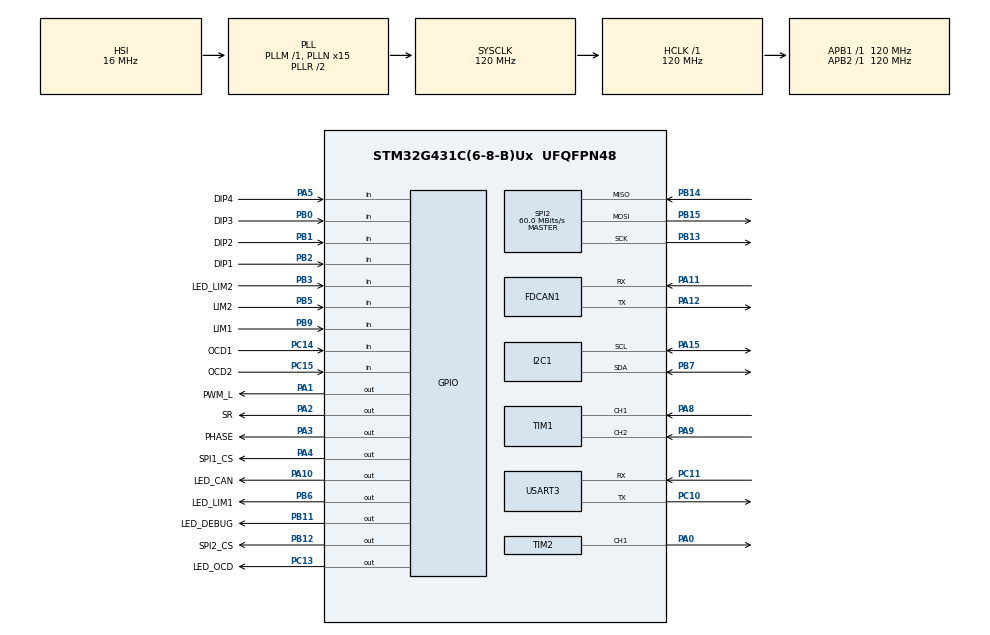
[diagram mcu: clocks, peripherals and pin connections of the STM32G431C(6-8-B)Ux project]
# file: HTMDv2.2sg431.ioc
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Dma.Request0=USART3_RX
Dma.Request1=USART3_TX
Dma.Request2=SPI2_RX
Dma.Request3=SPI2_TX
Dma.SPI2_RX.2.Direction=DMA_PERIPH_TO_MEMORY
Dma.SPI2_RX.2.EventEnable=DISABLE
Dma.SPI2_RX.2.Instance=DMA1_Channel5
Dma.SPI2_RX.2.MemDataAlignment=DMA_MDATAALIGN_BYTE
Dma.SPI2_RX.2.MemInc=DMA_MINC_ENABLE
Dma.SPI2_RX.2.Mode=DMA_NORMAL
Dma.SPI2_RX.2.PeriphDataAlignment=DMA_PDATAALIGN_BYTE
Dma.SPI2_RX.2.PeriphInc=DMA_PINC_DISABLE
Dma.SPI2_RX.2.Polarity=HAL_DMAMUX_REQ_GEN_RISING
Dma.SPI2_RX.2.Priority=DMA_PRIORITY_LOW
Dma.SPI2_RX.2.RequestNumber=1
Dma.SPI2_RX.2.SignalID=NONE
Dma.SPI2_RX.2.SyncEnable=DISABLE
Dma.SPI2_RX.2.SyncPolarity=HAL_DMAMUX_SYNC_NO_EVENT
Dma.SPI2_RX.2.SyncRequestNumber=1
Dma.SPI2_RX.2.SyncSignalID=NONE
Dma.SPI2_TX.3.Direction=DMA_MEMORY_TO_PERIPH
Dma.SPI2_TX.3.EventEnable=DISABLE
Dma.SPI2_TX.3.Instance=DMA1_Channel6
Dma.SPI2_TX.3.MemDataAlignment=DMA_MDATAALIGN_BYTE
Dma.SPI2_TX.3.MemInc=DMA_MINC_ENABLE
Dma.SPI2_TX.3.Mode=DMA_NORMAL
Dma.SPI2_TX.3.PeriphDataAlignment=DMA_PDATAALIGN_BYTE
Dma.SPI2_TX.3.PeriphInc=DMA_PINC_DISABLE
Dma.SPI2_TX.3.Polarity=HAL_DMAMUX_REQ_GEN_RISING
Dma.SPI2_TX.3.Priority=DMA_PRIORITY_LOW
Dma.SPI2_TX.3.RequestNumber=1
Dma.SPI2_TX.3.SignalID=NONE
Dma.SPI2_TX.3.SyncEnable=DISABLE
Dma.SPI2_TX.3.SyncPolarity=HAL_DMAMUX_SYNC_NO_EVENT
Dma.SPI2_TX.3.SyncRequestNumber=1
Dma.SPI2_TX.3.SyncSignalID=NONE
Dma.USART3_RX.0.Direction=DMA_PERIPH_TO_MEMORY
Dma.USART3_RX.0.EventEnable=DISABLE
Dma.USART3_RX.0.Instance=DMA1_Channel3
Dma.USART3_RX.0.MemDataAlignment=DMA_MDATAALIGN_BYTE
Dma.USART3_RX.0.MemInc=DMA_MINC_ENABLE
Dma.USART3_RX.0.Mode=DMA_NORMAL
Dma.USART3_RX.0.PeriphDataAlignment=DMA_PDATAALIGN_BYTE
Dma.USART3_RX.0.PeriphInc=DMA_PINC_DISABLE
Dma.USART3_RX.0.Polarity=HAL_DMAMUX_REQ_GEN_RISING
Dma.USART3_RX.0.Priority=DMA_PRIORITY_LOW
Dma.USART3_RX.0.RequestNumber=1
Dma.USART3_RX.0.SignalID=NONE
Dma.USART3_RX.0.SyncEnable=DISABLE
Dma.USART3_RX.0.SyncPolarity=HAL_DMAMUX_SYNC_NO_EVENT
Dma.USART3_RX.0.SyncRequestNumber=1
Dma.USART3_RX.0.SyncSignalID=NONE
Dma.USART3_TX.1.Direction=DMA_MEMORY_TO_PERIPH
Dma.USART3_TX.1.EventEnable=DISABLE
Dma.USART3_TX.1.Instance=DMA1_Channel4
Dma.USART3_TX.1.MemDataAlignment=DMA_MDATAALIGN_BYTE
Dma.USART3_TX.1.MemInc=DMA_MINC_ENABLE
Dma.USART3_TX.1.Mode=DMA_NORMAL
Dma.USART3_TX.1.PeriphDataAlignment=DMA_PDATAALIGN_BYTE
Dma.USART3_TX.1.PeriphInc=DMA_PINC_DISABLE
Dma.USART3_TX.1.Polarity=HAL_DMAMUX_REQ_GEN_RISING
Dma.USART3_TX.1.Priority=DMA_PRIORITY_LOW
Dma.USART3_TX.1.RequestNumber=1
Dma.USART3_TX.1.SignalID=NONE
Dma.USART3_TX.1.SyncEnable=DISABLE
Dma.USART3_TX.1.SyncPolarity=HAL_DMAMUX_SYNC_NO_EVENT
Dma.USART3_TX.1.SyncRequestNumber=1
Dma.USART3_TX.1.SyncSignalID=NONE
FDCAN1.CalculateBaudRateNominal=1000000
FDCAN1.CalculateTimeBitNominal=1000
FDCAN1.CalculateTimeQuantumNominal=100.0
FDCAN1.NominalPrescaler=3
FDCAN1.NominalTimeSeg1=7
FDCAN1.NominalTimeSeg2=2
I2C1.Timing=0x307075B1
Mcu.Family=STM32G4
Mcu.Name=STM32G431C(6-8-B)Ux
Mcu.Package=UFQFPN48
NVIC.DMA1_Channel3_IRQn=true\:0\:0\:false\:false\:true\:false\:true\:true
NVIC.DMA1_Channel4_IRQn=true\:0\:0\:false\:false\:true\:false\:true\:true
NVIC.DMA1_Channel5_IRQn=true\:0\:0\:false\:false\:true\:false\:true\:true
NVIC.DMA1_Channel6_IRQn=true\:0\:0\:false\:false\:true\:false\:true\:true
NVIC.FDCAN1_IT0_IRQn=true\:0\:0\:false\:false\:true\:true\:true\:true
NVIC.I2C1_ER_IRQn=true\:0\:0\:false\:false\:true\:true\:true\:true
NVIC.I2C1_EV_IRQn=true\:0\:0\:false\:false\:true\:true\:true\:true
NVIC.PriorityGroup=NVIC_PRIORITYGROUP_4
NVIC.TIM3_IRQn=true\:0\:0\:false\:false\:true\:true\:true\:true
NVIC.TIM4_IRQn=true\:0\:0\:false\:false\:true\:true\:true\:true
PA0.Signal=S_TIM2_CH1
PA1.GPIO_Label=PWM_L
PA1.Signal=GPIO_Output
PA10.GPIO_Label=LED_CAN
PA10.Signal=GPIO_Output
PA11.Mode=FDCAN_Activate
PA11.Signal=FDCAN1_RX
PA12.Mode=FDCAN_Activate
PA12.Signal=FDCAN1_TX
PA13.Mode=Serial_Wire
PA13.Signal=SYS_JTMS-SWDIO
PA14.Mode=Serial_Wire
PA14.Signal=SYS_JTCK-SWCLK
PA15.GPIO_Pu=GPIO_NOPULL
PA15.GPIO_Speed=GPIO_SPEED_FREQ_VERY_HIGH
PA15.Mode=I2C
PA15.Signal=I2C1_SCL
PA2.GPIO_Label=SR
PA2.Signal=GPIO_Output
PA3.GPIO_Label=PHASE
PA3.Signal=GPIO_Output
PA4.GPIO_Label=SPI1_CS
PA4.Signal=GPIO_Output
PA5.GPIO_Label=DIP4
PA5.GPIO_PuPd=GPIO_PULLDOWN
PA5.Signal=GPIO_Input
PA8.Signal=S_TIM1_CH1
PA9.Signal=S_TIM1_CH2
PB0.GPIO_Label=DIP3
PB0.GPIO_PuPd=GPIO_PULLDOWN
PB0.Signal=GPIO_Input
PB1.GPIO_Label=DIP2
PB1.GPIO_PuPd=GPIO_PULLDOWN
PB1.Signal=GPIO_Input
PB11.GPIO_Label=LED_DEBUG
PB11.Signal=GPIO_Output
PB12.GPIO_Label=SPI2_CS
PB12.Signal=GPIO_Output
PB13.Mode=Full_Duplex_Master
PB13.Signal=SPI2_SCK
PB14.Mode=Full_Duplex_Master
PB14.Signal=SPI2_MISO
PB15.Mode=Full_Duplex_Master
PB15.Signal=SPI2_MOSI
PB2.GPIO_Label=DIP1
PB2.GPIO_PuPd=GPIO_PULLDOWN
PB2.Signal=GPIO_Input
PB3.GPIO_Label=LED_LIM2
PB3.Signal=GPIO_Input
PB5.GPIO_Label=LIM2
PB5.GPIO_PuPd=GPIO_NOPULL
PB5.Signal=GPIO_Input
PB6.GPIO_Label=LED_LIM1
PB6.Signal=GPIO_Output
PB7.GPIO_Pu=GPIO_NOPULL
PB7.GPIO_Speed=GPIO_SPEED_FREQ_VERY_HIGH
PB7.Mode=I2C
PB7.Signal=I2C1_SDA
PB9.GPIO_Label=LIM1
PB9.Signal=GPIO_Input
PC10.Mode=Asynchronous
PC10.Signal=USART3_TX
PC11.Mode=Asynchronous
PC11.Signal=USART3_RX
PC13.GPIO_Label=LED_OCD
PC13.Signal=GPIO_Output
PC14-OSC32_IN.GPIO_Label=OCD1
PC14-OSC32_IN.Signal=GPIO_Input
PC15-OSC32_OUT.GPIO_Label=OCD2
PC15-OSC32_OUT.Signal=GPIO_Input
ProjectManager.HeapSize=0x200
ProjectManager.StackSize=0x400
ProjectManager.TargetToolchain=Makefile
RCC.ADC12Freq_Value=120000000
RCC.AHBFreq_Value=120000000
RCC.APB1Freq_Value=120000000
RCC.APB1TimFreq_Value=120000000
RCC.APB2Freq_Value=120000000
RCC.APB2TimFreq_Value=120000000
RCC.CortexFreq_Value=120000000
RCC.EXTERNAL_CLOCK_VALUE=12288000
RCC.FDCANCLockSelection=RCC_FDCANCLKSOURCE_PLL
RCC.HCLKFreq_Value=120000000
RCC.HSE_VALUE=8000000
RCC.HSI48_VALUE=48000000
RCC.HSI_VALUE=16000000
RCC.LSE_VALUE=32768
RCC.PLLN=15
RCC.PLLQ=RCC_PLLQ_DIV8
RCC.SYSCLKFreq_VALUE=120000000
RCC.SYSCLKSource=RCC_SYSCLKSOURCE_PLLCLK
RCC.USBFreq_Value=30000000
RCC.VCOOutputFreq_Value=240000000
SH.S_TIM1_CH1.0=TIM1_CH1,Encoder_Interface
SH.S_TIM1_CH2.0=TIM1_CH2,Encoder_Interface
SH.S_TIM2_CH1.0=TIM2_CH1,PWM Generation1 CH1
SPI2.CalculateBaudRate=60.0 MBits/s
SPI2.Direction=SPI_DIRECTION_2LINES
SPI2.Mode=SPI_MODE_MASTER
SPI2.VirtualType=VM_MASTER
TIM1.EncoderMode=TIM_ENCODERMODE_TI12
TIM2.Channel-PWM\ Generation1\ CH1=TIM_CHANNEL_1
TIM2.PeriodNoDither=5999
TIM2.Prescaler=0
TIM3.PeriodNoDither=999
TIM3.Prescaler=120
TIM4.PeriodNoDither=9999
TIM4.Prescaler=120
USART3.VirtualMode-Asynchronous=VM_ASYNC
VP_SYS_VS_DBSignals.Mode=DisableDeadBatterySignals
VP_TIM2_VS_ClockSourceINT.Mode=Internal
VP_TIM3_VS_ClockSourceINT.Mode=Internal
VP_TIM4_VS_ClockSourceINT.Mode=Internal
board=custom

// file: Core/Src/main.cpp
/* USER CODE BEGIN Header */
/**
 ******************************************************************************
 * @file           : main.c
 * @brief          : Main program body
 ******************************************************************************
 * @attention
 *
 * Copyright (c) 2024 STMicroelectronics.
 * All rights reserved.
 *
 * This software is licensed under terms that can be found in the LICENSE file
 * in the root directory of this software component.
 * If no LICENSE file comes with this software, it is provided AS-IS.
 *
 ******************************************************************************
 */
/* USER CODE END Header */
#include "main.h"
#include "dma.h"
#include "fdcan.h"
#include "i2c.h"
#include "spi.h"
#include "tim.h"
#include "usart.h"
#include "gpio.h"

/* USER CODE BEGIN Includes */
#include "app.hpp"

/* USER CODE END Includes */

void SystemClock_Config(void);

/* USER CODE BEGIN 0 */
App app;

/* USER CODE END 0 */

int main(void)
{

  /* MCU Configuration--------------------------------------------------------*/

  /* Reset of all peripherals, Initializes the Flash interface and the Systick. */
  HAL_Init();

  /* Configure the system clock */
  SystemClock_Config();

  /* Initialize all configured peripherals */
  MX_GPIO_Init();
  MX_DMA_Init();
  MX_FDCAN1_Init();
  MX_I2C1_Init();
  MX_TIM1_Init();
  MX_TIM2_Init();
  MX_USART3_UART_Init();
  MX_SPI2_Init();
  MX_TIM4_Init();
  MX_TIM3_Init();
  /* USER CODE BEGIN 2 */
  app.init();
  /* USER CODE END 2 */

  /* Infinite loop */
  while (1)
  {

    /* USER CODE BEGIN 3 */
    app.mainLoop();
  }
  /* USER CODE END 3 */
}

void SystemClock_Config(void)
{
  RCC_OscInitTypeDef RCC_OscInitStruct = {0};
  RCC_ClkInitTypeDef RCC_ClkInitStruct = {0};

  /** Configure the main internal regulator output voltage
   */
  HAL_PWREx_ControlVoltageScaling(PWR_REGULATOR_VOLTAGE_SCALE1);

  /** Initializes the RCC Oscillators according to the specified parameters
   * in the RCC_OscInitTypeDef structure.
   */
  RCC_OscInitStruct.OscillatorType = RCC_OSCILLATORTYPE_HSI;
  RCC_OscInitStruct.HSIState = RCC_HSI_ON;
  RCC_OscInitStruct.HSICalibrationValue = RCC_HSICALIBRATION_DEFAULT;
  RCC_OscInitStruct.PLL.PLLState = RCC_PLL_ON;
  RCC_OscInitStruct.PLL.PLLSource = RCC_PLLSOURCE_HSI;
  RCC_OscInitStruct.PLL.PLLM = RCC_PLLM_DIV1;
  RCC_OscInitStruct.PLL.PLLN = 15;
  RCC_OscInitStruct.PLL.PLLP = RCC_PLLP_DIV2;
  RCC_OscInitStruct.PLL.PLLQ = RCC_PLLQ_DIV8;
  RCC_OscInitStruct.PLL.PLLR = RCC_PLLR_DIV2;
  if (HAL_RCC_OscConfig(&RCC_OscInitStruct) != HAL_OK)
  {
    Error_Handler();
  }

  /** Initializes the CPU, AHB and APB buses clocks
   */
  RCC_ClkInitStruct.ClockType = RCC_CLOCKTYPE_HCLK | RCC_CLOCKTYPE_SYSCLK | RCC_CLOCKTYPE_PCLK1 | RCC_CLOCKTYPE_PCLK2;
  RCC_ClkInitStruct.SYSCLKSource = RCC_SYSCLKSOURCE_PLLCLK;
  RCC_ClkInitStruct.AHBCLKDivider = RCC_SYSCLK_DIV1;
  RCC_ClkInitStruct.APB1CLKDivider = RCC_HCLK_DIV1;
  RCC_ClkInitStruct.APB2CLKDivider = RCC_HCLK_DIV1;

  if (HAL_RCC_ClockConfig(&RCC_ClkInitStruct, FLASH_LATENCY_3) != HAL_OK)
  {
    Error_Handler();
  }
}

/* USER CODE BEGIN 4 */
void HAL_FDCAN_RxFifo0Callback(FDCAN_HandleTypeDef *hfdcan, uint32_t RxFifo0ITs)
{
  app.CANCallbackProcess(hfdcan, RxFifo0ITs);
}

void HAL_TIM_PeriodElapsedCallback(TIM_HandleTypeDef *htim)
{
  if (htim->Instance == TIM4)
  {
    app.timerTask();
  }
}
/* USER CODE END 4 */

void Error_Handler(void)
{
  __disable_irq();
  while (1)
  {
  }
}
